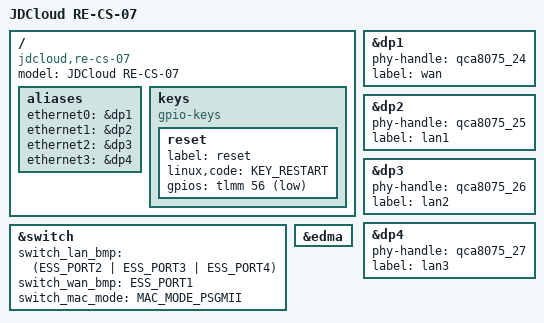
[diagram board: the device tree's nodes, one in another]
// SPDX-License-Identifier: GPL-2.0-or-later OR MIT

/dts-v1/;

#include "ipq6010-re-cs.dtsi"

/ {
	model = "JDCloud RE-CS-07";
	compatible = "jdcloud,re-cs-07", "qcom,ipq6018";

	aliases {
		ethernet0 = &dp1;
		ethernet1 = &dp2;
		ethernet2 = &dp3;
		ethernet3 = &dp4;
	};

	keys {
		compatible = "gpio-keys";

		reset {
			label = "reset";
			linux,code = <KEY_RESTART>;
			gpios = <&tlmm 56 GPIO_ACTIVE_LOW>;
		};
	};
};

&switch {
	switch_lan_bmp = <(ESS_PORT2 | ESS_PORT3 | ESS_PORT4)>;
	switch_wan_bmp = <ESS_PORT1>;
	switch_mac_mode = <MAC_MODE_PSGMII>;
};

&dp1 {
	status = "okay";
	phy-handle = <&qca8075_24>;
	label = "wan";
};

&dp2 {
	status = "okay";
	phy-handle = <&qca8075_25>;
	label = "lan1";
};

&dp3 {
	status = "okay";
	phy-handle = <&qca8075_26>;
	label = "lan2";
};

&dp4 {
	status = "okay";
	phy-handle = <&qca8075_27>;
	label = "lan3";
};

&edma {
	status = "okay";
};
